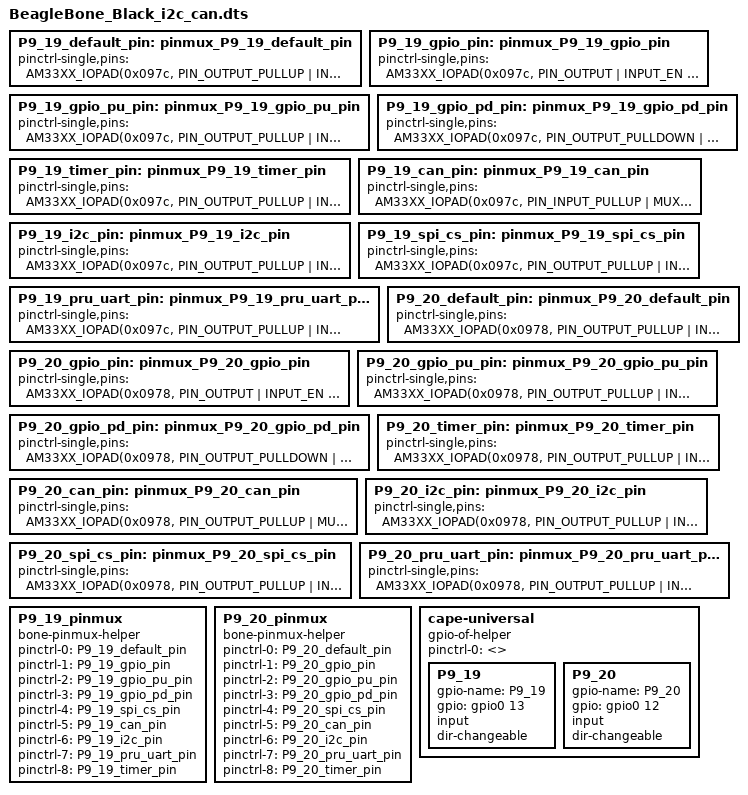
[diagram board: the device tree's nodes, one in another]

/* P9_19:D17:uart1_rtsn:0:O */
/* P9_19:D17:timer5:1:IO */
/* P9_19:D17:dcan0_rx:2:I */
/* P9_19:D17:i2c2_scl:3:IOD */
/* P9_19:D17:spi1_cs1:4:IO */
/* P9_19:D17:pr1_uart0_rts_n:5:O */
/* P9_19:D17:pr1_edc_latch1_in:6:I */
/* P9_19:D17:gpio0_13:7:IO */
/* P9_19 (ZCZ ball D17) i2c2_scl */
P9_19_default_pin: pinmux_P9_19_default_pin { pinctrl-single,pins = <
	AM33XX_IOPAD(0x097c, PIN_OUTPUT_PULLUP | INPUT_EN | MUX_MODE3) >; };	/* uart1_rtsn.i2c2_scl */
P9_19_gpio_pin: pinmux_P9_19_gpio_pin { pinctrl-single,pins = <
	AM33XX_IOPAD(0x097c, PIN_OUTPUT | INPUT_EN | MUX_MODE7) >; };		/* uart1_rtsn.gpio0_13 */
P9_19_gpio_pu_pin: pinmux_P9_19_gpio_pu_pin { pinctrl-single,pins = <
	AM33XX_IOPAD(0x097c, PIN_OUTPUT_PULLUP | INPUT_EN | MUX_MODE7) >; };	/* uart1_rtsn.gpio0_13 */
P9_19_gpio_pd_pin: pinmux_P9_19_gpio_pd_pin { pinctrl-single,pins = <
	AM33XX_IOPAD(0x097c, PIN_OUTPUT_PULLDOWN | INPUT_EN | MUX_MODE7) >; };	/* uart1_rtsn.gpio0_13 */
P9_19_timer_pin: pinmux_P9_19_timer_pin { pinctrl-single,pins = <
	AM33XX_IOPAD(0x097c, PIN_OUTPUT_PULLUP | INPUT_EN | MUX_MODE1) >; };	/* uart1_rtsn.timer5 */
P9_19_can_pin: pinmux_P9_19_can_pin { pinctrl-single,pins = <
	AM33XX_IOPAD(0x097c, PIN_INPUT_PULLUP | MUX_MODE2) >; };		/* uart1_rtsn.dcan0_rx */
P9_19_i2c_pin: pinmux_P9_19_i2c_pin { pinctrl-single,pins = <
	AM33XX_IOPAD(0x097c, PIN_OUTPUT_PULLUP | INPUT_EN | MUX_MODE3) >; };	/* uart1_rtsn.i2c2_scl */
P9_19_spi_cs_pin: pinmux_P9_19_spi_cs_pin { pinctrl-single,pins = <
	AM33XX_IOPAD(0x097c, PIN_OUTPUT_PULLUP | INPUT_EN | MUX_MODE4) >; };	/* uart1_rtsn.spi1_cs1 */
P9_19_pru_uart_pin: pinmux_P9_19_pru_uart_pin { pinctrl-single,pins = <
	AM33XX_IOPAD(0x097c, PIN_OUTPUT_PULLUP | INPUT_EN | MUX_MODE5) >; };	/* uart1_rtsn.pr1_uart0_rts_n */

/* P9_20:D18:uart1_ctsn:0:I */
/* P9_20:D18:timer6:1:IO */
/* P9_20:D18:dcan0_tx:2:O */
/* P9_20:D18:i2c2_sda:3:IOD */
/* P9_20:D18:spi1_cs0:4:IO */
/* P9_20:D18:pr1_uart0_cts_n:5:I */
/* P9_20:D18:pr1_edc_latch0_in:6:I */
/* P9_20:D18:gpio0_12:7:IO */
/* P9_20 (ZCZ ball D18) i2c2_sda */
P9_20_default_pin: pinmux_P9_20_default_pin { pinctrl-single,pins = <
	AM33XX_IOPAD(0x0978, PIN_OUTPUT_PULLUP | INPUT_EN | MUX_MODE3) >; };	/* uart1_ctsn.i2c2_sda */
P9_20_gpio_pin: pinmux_P9_20_gpio_pin { pinctrl-single,pins = <
	AM33XX_IOPAD(0x0978, PIN_OUTPUT | INPUT_EN | MUX_MODE7) >; };		/* uart1_ctsn.gpio0_12 */
P9_20_gpio_pu_pin: pinmux_P9_20_gpio_pu_pin { pinctrl-single,pins = <
	AM33XX_IOPAD(0x0978, PIN_OUTPUT_PULLUP | INPUT_EN | MUX_MODE7) >; };	/* uart1_ctsn.gpio0_12 */
P9_20_gpio_pd_pin: pinmux_P9_20_gpio_pd_pin { pinctrl-single,pins = <
	AM33XX_IOPAD(0x0978, PIN_OUTPUT_PULLDOWN | INPUT_EN | MUX_MODE7) >; };	/* uart1_ctsn.gpio0_12 */
P9_20_timer_pin: pinmux_P9_20_timer_pin { pinctrl-single,pins = <
	AM33XX_IOPAD(0x0978, PIN_OUTPUT_PULLUP | INPUT_EN | MUX_MODE1) >; };	/* uart1_ctsn.timer6 */
P9_20_can_pin: pinmux_P9_20_can_pin { pinctrl-single,pins = <
	AM33XX_IOPAD(0x0978, PIN_OUTPUT_PULLUP | MUX_MODE2) >; };		/* uart1_ctsn.dcan0_tx */
P9_20_i2c_pin: pinmux_P9_20_i2c_pin { pinctrl-single,pins = <
	AM33XX_IOPAD(0x0978, PIN_OUTPUT_PULLUP | INPUT_EN | MUX_MODE3) >; };	/* uart1_ctsn.i2c2_sda */
P9_20_spi_cs_pin: pinmux_P9_20_spi_cs_pin { pinctrl-single,pins = <
	AM33XX_IOPAD(0x0978, PIN_OUTPUT_PULLUP | INPUT_EN | MUX_MODE4) >; };	/* uart1_ctsn.spi1_cs0 */
P9_20_pru_uart_pin: pinmux_P9_20_pru_uart_pin { pinctrl-single,pins = <
	AM33XX_IOPAD(0x0978, PIN_OUTPUT_PULLUP | INPUT_EN | MUX_MODE5) >; };	/* uart1_ctsn.pr1_uart0_cts_n */



/* P9_19 (ZCZ ball D17) i2c */
P9_19_pinmux {
	compatible = "bone-pinmux-helper";
	status = "okay";
	pinctrl-names = "default", "gpio", "gpio_pu", "gpio_pd", "spi_cs", "can", "i2c", "pru_uart", "timer";
	pinctrl-0 = <&P9_19_default_pin>;
	pinctrl-1 = <&P9_19_gpio_pin>;
	pinctrl-2 = <&P9_19_gpio_pu_pin>;
	pinctrl-3 = <&P9_19_gpio_pd_pin>;
	pinctrl-4 = <&P9_19_spi_cs_pin>;
	pinctrl-5 = <&P9_19_can_pin>;
	pinctrl-6 = <&P9_19_i2c_pin>;
	pinctrl-7 = <&P9_19_pru_uart_pin>;
	pinctrl-8 = <&P9_19_timer_pin>;
};

/* P9_20 (ZCZ ball D18) i2c */
P9_20_pinmux {
	compatible = "bone-pinmux-helper";
	status = "okay";
	pinctrl-names = "default", "gpio", "gpio_pu", "gpio_pd", "spi_cs", "can", "i2c", "pru_uart", "timer";
	pinctrl-0 = <&P9_20_default_pin>;
	pinctrl-1 = <&P9_20_gpio_pin>;
	pinctrl-2 = <&P9_20_gpio_pu_pin>;
	pinctrl-3 = <&P9_20_gpio_pd_pin>;
	pinctrl-4 = <&P9_20_spi_cs_pin>;
	pinctrl-5 = <&P9_20_can_pin>;
	pinctrl-6 = <&P9_20_i2c_pin>;
	pinctrl-7 = <&P9_20_pru_uart_pin>;
	pinctrl-8 = <&P9_20_timer_pin>;
};


cape-universal {
	compatible = "gpio-of-helper";
	status = "okay";
	pinctrl-names = "default";
	pinctrl-0 = <>;

	P9_19 {
		gpio-name = "P9_19";
		gpio = <&gpio0 13 0>;
		input;
		dir-changeable;
	};

	P9_20 {
		gpio-name = "P9_20";
		gpio = <&gpio0 12 0>;
		input;
		dir-changeable;
	};

};
